AUTOSAR XML (schema 4-2-2)
package /EB/SoftwareComponents
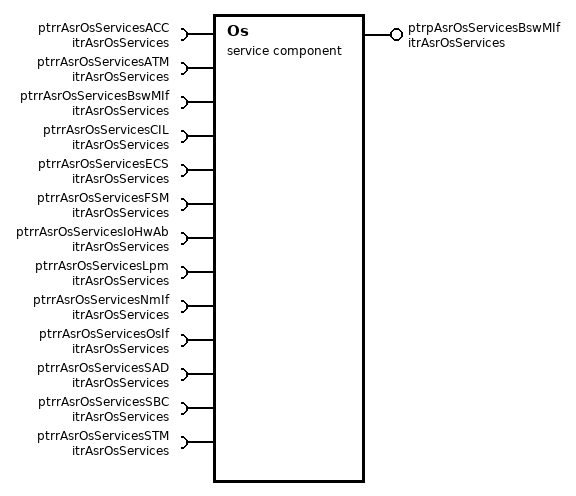
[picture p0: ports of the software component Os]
  service sw component type Os: category=ASR_Interfaces
    provide port ptrpAsrOsServicesBswMIf: provided-interface=itrAsrOsServices
    13 x require port, all with required-interface=itrAsrOsServices:
      ptrrAsrOsServicesACC
      ptrrAsrOsServicesATM
      ptrrAsrOsServicesBswMIf
      ptrrAsrOsServicesCIL
      ptrrAsrOsServicesECS
      ptrrAsrOsServicesFSM
      ptrrAsrOsServicesIoHwAb
      ptrrAsrOsServicesLpm
      ptrrAsrOsServicesNmIf
      ptrrAsrOsServicesOsIf
      ptrrAsrOsServicesSAD
      ptrrAsrOsServicesSBC
      ptrrAsrOsServicesSTM
    behavior Os_IB: handle-termination-and-restart=NO-SUPPORT
      20 x external trigger occurred event:
        trACC_GetAccelerometerData: start-on-event=OsTask_Alv_eCS_App, trigger=ptrrAsrOsServicesOsIf.ACC_GetAccelerometerData
        trATM_runMainFunction: start-on-event=OsTask_Alv_Autotests, trigger=ptrrAsrOsServicesOsIf.ATM_runMainFunction
        trCIL_runAppliToCAN: start-on-event=OsTask_Alv_Com, trigger=ptrrAsrOsServicesOsIf.CIL_runAppliToCAN
        trCIL_runCANToAppli: start-on-event=OsTask_Alv_Com, trigger=ptrrAsrOsServicesOsIf.CIL_runCANToAppli
        trCIL_runManageMF: start-on-event=OsTask_Alv_Com, trigger=ptrrAsrOsServicesOsIf.CIL_runManageMF
        trErrorHookOsError: start-on-event=OS_Error, trigger=ptrrAsrOsServicesOsIf.ErrorHook
        trErrorHookOsErrorMinimal: start-on-event=OS_ErrorMinimal, trigger=ptrrAsrOsServicesOsIf.ErrorHook
        trErrorHookOsErrorMinimalParam: start-on-event=OS_ErrorMinimalParam, trigger=ptrrAsrOsServicesOsIf.ErrorHook
        trFSM_runCheckVehicleInputs: start-on-event=OsTask_Alv_eCS_App, trigger=ptrrAsrOsServicesOsIf
        trFSM_runMainFunction: start-on-event=OsTask_Alv_eCS_App, trigger=ptrrAsrOsServicesOsIf.FSM_runMainFunction
        trIoHwAb_runFilterMeasurements100ms: start-on-event=OsTask_Alv_Autotests, trigger=ptrrAsrOsServicesIoHwAb.IoHwAb_runFilterMeasurements100ms
        trIoHwAb_runFilterMeasurements10ms: start-on-event=OsTask_Alv_Autotests, trigger=ptrrAsrOsServicesIoHwAb.IoHwAb_runFilterMeasurements10ms
        trIoHwAb_runFilterMeasurements2ms: start-on-event=OsTask_Alv_Autotests, trigger=ptrrAsrOsServicesIoHwAb.IoHwAb_runFilterMeasurements2ms
        trOsTask_Bsw_Init: start-on-event=OsTaskAutostart, trigger=ptrrAsrOsServicesOsIf.OsTask_Bsw_Init
        trProtectionHook: start-on-event=OS_Error, trigger=ptrrAsrOsServicesOsIf.ProtectionHook
        trSAD_runMainFunction: start-on-event=OsTask_Alv_eCS_App, trigger=ptrrAsrOsServicesOsIf.SAD_runMainFunction
        trSBC_runMainFunction: start-on-event=OsTask_Alv_Wdg_Refresh, trigger=ptrrAsrOsServicesOsIf.SBC_runMainFunction
        trSTM_runIncreaseSystemTime: start-on-event=OsTask_Alv_Com, trigger=ptrrAsrOsServicesOsIf.STM_runIncreaseSystemTime
        trT1_AppBackgroundHandler: start-on-event=OsTask_AppIdle, trigger=T1_AppBackgroundHandler
        treCS_runMainFunction: start-on-event=OsTask_Alv_eCS_App, trigger=ptrrAsrOsServicesOsIf.eCS_runMainFunction
      22 x runnable:
        OS_Error
        OS_ErrorMinimal
        OS_ErrorMinimalParam
        OS_FastResumeAllInterrupts
        OS_FastSuspendAllInterrupts
        OS_UserActivateTask
        OS_UserClearEvent
        OS_UserSetEvent
        OS_UserStartScheduleTable
        OS_UserStopScheduleTable
        OS_UserTerminateTask
        OS_UserWaitEvent
        OsTaskAutostart: symbol=OsTaskAutostart_OsApplication_0
        OsTask_Alv_Autotests: symbol=OsTask_Alv_Autotests_OsApplication_0
        OsTask_Alv_Com: symbol=OsTask_Alv_Com_OsApplication_0
        OsTask_Alv_Wdg_Refresh: symbol=OsTask_Alv_Wdg_Refresh_OsApplication_0
        OsTask_Alv_eCS_App: symbol=OsTask_Alv_eCS_App_OsApplication_0
        OsTask_AppIdle
        OsTask_Bsw_Com: symbol=OsTask_Bsw_Com_OsApplication_0
        OsTask_Bsw_Events: symbol=OsTask_Bsw_Events_OsApplication_0
        OsTask_Bsw_Mem: symbol=OsTask_Bsw_Mem_OsApplication_0
        OsTask_Bsw_Rte: symbol=OsTask_Bsw_Rte_OsApplication_0
package /EB/TriggerInterfaces
  trigger interface itrAsrOsServices
    35 x trigger:
      ACC_GetAccelerometerData: trigger-period={cse-code=3, cse-code-factor=1}
      ATM_runMainFunction: trigger-period={cse-code=3, cse-code-factor=2}
      BswMIf_runMainFunction: trigger-period={cse-code=1000, cse-code-factor=0}
      CIL_runAppliToCAN: trigger-period={cse-code=3, cse-code-factor=10}
      CIL_runCANToAppli: trigger-period={cse-code=3, cse-code-factor=10}
      CIL_runCANToSafetyAppli: trigger-period={cse-code=3, cse-code-factor=10}
      CIL_runManageMF: trigger-period={cse-code=3, cse-code-factor=5}
      ErrorHook: trigger-period={cse-code=1000, cse-code-factor=0}
      FSM_runMainFunction: trigger-period={cse-code=0, cse-code-factor=500}
      FSM_runUpdateModeStatus: trigger-period={cse-code=1000, cse-code-factor=0}
      IoHwAb_DetectVoltageFluctuation: trigger-period={cse-code=1000, cse-code-factor=0}
      IoHwAb_runFilterMeasurements100ms: trigger-period={cse-code=1000, cse-code-factor=0}
      IoHwAb_runFilterMeasurements10ms: trigger-period={cse-code=1000, cse-code-factor=0}
      IoHwAb_runFilterMeasurements2ms: trigger-period={cse-code=1000, cse-code-factor=0}
      LPTMR_ISR: trigger-period={cse-code=1000, cse-code-factor=0}
      NmIf_runMainFunction: trigger-period={cse-code=1000, cse-code-factor=0}
      OS_FastResumeAllInterrupts: trigger-period={cse-code=1000, cse-code-factor=0}
      OS_FastSuspendAllInterrupts: trigger-period={cse-code=1000, cse-code-factor=0}
      OS_UserActivateTask: trigger-period={cse-code=1000, cse-code-factor=0}
      OS_UserClearEvent: trigger-period={cse-code=1000, cse-code-factor=0}
      OS_UserSetEvent: trigger-period={cse-code=1000, cse-code-factor=0}
      OS_UserStartScheduleTable: trigger-period={cse-code=1000, cse-code-factor=0}
      OS_UserStopScheduleTable: trigger-period={cse-code=1000, cse-code-factor=0}
      OS_UserTerminateTask: trigger-period={cse-code=1000, cse-code-factor=0}
      OS_UserWaitEvent: trigger-period={cse-code=1000, cse-code-factor=0}
      OsTask_Alv_Wdg_Refresh: trigger-period={cse-code=1000, cse-code-factor=0}
      OsTask_Bsw_Init: trigger-period={cse-code=1000, cse-code-factor=0}
      OsTask_Bsw_ReadWrite_AllProcess: trigger-period={cse-code=1000, cse-code-factor=0}
      PORTD_ISR: trigger-period={cse-code=1000, cse-code-factor=0}
      ProtectionHook: trigger-period={cse-code=1000, cse-code-factor=0}
      SAD_runMainFunction: trigger-period={cse-code=0, cse-code-factor=500}
      SBC_runMainFunction: trigger-period={cse-code=3, cse-code-factor=10}
      STM_runIncreaseSystemTime: trigger-period={cse-code=3, cse-code-factor=10}
      T1_AppBackgroundHandler: trigger-period={cse-code=1000, cse-code-factor=0}
      eCS_runMainFunction: trigger-period={cse-code=0, cse-code-factor=500}
